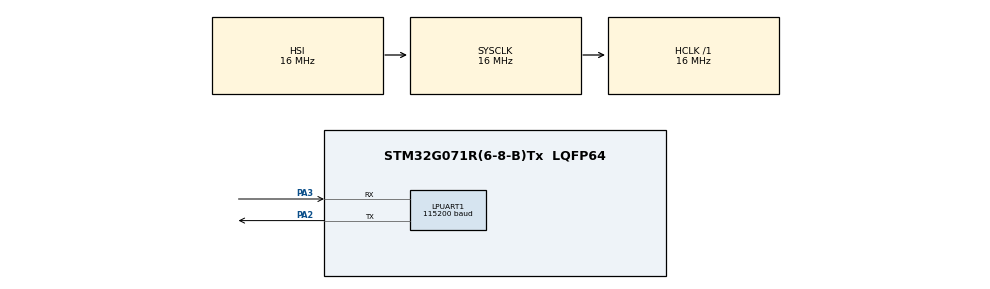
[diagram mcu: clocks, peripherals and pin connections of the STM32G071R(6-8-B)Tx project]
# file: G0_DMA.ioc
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Dma.LPUART1_RX.0.Direction=DMA_PERIPH_TO_MEMORY
Dma.LPUART1_RX.0.EventEnable=DISABLE
Dma.LPUART1_RX.0.Instance=DMA1_Channel1
Dma.LPUART1_RX.0.MemDataAlignment=DMA_MDATAALIGN_BYTE
Dma.LPUART1_RX.0.MemInc=DMA_MINC_ENABLE
Dma.LPUART1_RX.0.Mode=DMA_NORMAL
Dma.LPUART1_RX.0.PeriphDataAlignment=DMA_PDATAALIGN_BYTE
Dma.LPUART1_RX.0.PeriphInc=DMA_PINC_DISABLE
Dma.LPUART1_RX.0.Polarity=HAL_DMAMUX_REQ_GEN_RISING
Dma.LPUART1_RX.0.Priority=DMA_PRIORITY_LOW
Dma.LPUART1_RX.0.RequestNumber=1
Dma.LPUART1_RX.0.SyncEnable=DISABLE
Dma.LPUART1_RX.0.SyncPolarity=HAL_DMAMUX_SYNC_NO_EVENT
Dma.LPUART1_RX.0.SyncRequestNumber=1
Dma.LPUART1_TX.1.Direction=DMA_MEMORY_TO_PERIPH
Dma.LPUART1_TX.1.EventEnable=DISABLE
Dma.LPUART1_TX.1.Instance=DMA1_Channel2
Dma.LPUART1_TX.1.MemDataAlignment=DMA_MDATAALIGN_BYTE
Dma.LPUART1_TX.1.MemInc=DMA_MINC_ENABLE
Dma.LPUART1_TX.1.Mode=DMA_NORMAL
Dma.LPUART1_TX.1.PeriphDataAlignment=DMA_PDATAALIGN_BYTE
Dma.LPUART1_TX.1.PeriphInc=DMA_PINC_DISABLE
Dma.LPUART1_TX.1.Polarity=HAL_DMAMUX_REQ_GEN_RISING
Dma.LPUART1_TX.1.Priority=DMA_PRIORITY_LOW
Dma.LPUART1_TX.1.RequestNumber=1
Dma.LPUART1_TX.1.SyncEnable=DISABLE
Dma.LPUART1_TX.1.SyncPolarity=HAL_DMAMUX_SYNC_NO_EVENT
Dma.LPUART1_TX.1.SyncRequestNumber=1
Dma.Request0=LPUART1_RX
Dma.Request1=LPUART1_TX
LPUART1.BaudRate=115200
LPUART1.WordLength=UART_WORDLENGTH_8B
Mcu.Family=STM32G0
Mcu.Name=STM32G071R(6-8-B)Tx
Mcu.Package=LQFP64
NVIC.DMA1_Channel1_IRQn=true\:0\:0\:false\:false\:true\:false
NVIC.DMA1_Channel2_3_IRQn=true\:0\:0\:false\:false\:true\:false
PA2.Mode=Asynchronous
PA2.Signal=LPUART1_TX
PA3.Mode=Asynchronous
PA3.Signal=LPUART1_RX
ProjectManager.HeapSize=0x200
ProjectManager.StackSize=0x400
ProjectManager.TargetToolchain=MDK-ARM V5
RCC.AHBFreq_Value=16000000
RCC.CortexFreq_Value=16000000
RCC.EXTERNAL_CLOCK_VALUE=48000
RCC.HCLKFreq_Value=16000000
RCC.HSE_VALUE=8000000
RCC.HSI_VALUE=16000000
RCC.LSE_VALUE=32768
RCC.SYSCLKFreq_VALUE=16000000
RCC.VCOOutputFreq_Value=128000000
board=custom

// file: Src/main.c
/* USER CODE BEGIN Header */
/**
  ******************************************************************************
  * @file           : main.c
  * @brief          : Main program body
  ******************************************************************************
  ** This notice applies to any and all portions of this file
  * that are not between comment pairs USER CODE BEGIN and
  * USER CODE END. Other portions of this file, whether
  * inserted by the user or by software development tools
  * are owned by their respective copyright owners.
  *
  * COPYRIGHT(c) 2019 STMicroelectronics
  *
  * Redistribution and use in source and binary forms, with or without modification,
  * are permitted provided that the following conditions are met:
  *   1. Redistributions of source code must retain the above copyright notice,
  *      this list of conditions and the following disclaimer.
  *   2. Redistributions in binary form must reproduce the above copyright notice,
  *      this list of conditions and the following disclaimer in the documentation
  *      and/or other materials provided with the distribution.
  *   3. Neither the name of STMicroelectronics nor the names of its contributors
  *      may be used to endorse or promote products derived from this software
  *      without specific prior written permission.
  *
  * THIS SOFTWARE IS PROVIDED BY THE COPYRIGHT HOLDERS AND CONTRIBUTORS "AS IS"
  * AND ANY EXPRESS OR IMPLIED WARRANTIES, INCLUDING, BUT NOT LIMITED TO, THE
  * IMPLIED WARRANTIES OF MERCHANTABILITY AND FITNESS FOR A PARTICULAR PURPOSE ARE
  * DISCLAIMED. IN NO EVENT SHALL THE COPYRIGHT HOLDER OR CONTRIBUTORS BE LIABLE
  * FOR ANY DIRECT, INDIRECT, INCIDENTAL, SPECIAL, EXEMPLARY, OR CONSEQUENTIAL
  * DAMAGES (INCLUDING, BUT NOT LIMITED TO, PROCUREMENT OF SUBSTITUTE GOODS OR
  * SERVICES; LOSS OF USE, DATA, OR PROFITS; OR BUSINESS INTERRUPTION) HOWEVER
  * CAUSED AND ON ANY THEORY OF LIABILITY, WHETHER IN CONTRACT, STRICT LIABILITY,
  * OR TORT (INCLUDING NEGLIGENCE OR OTHERWISE) ARISING IN ANY WAY OUT OF THE USE
  * OF THIS SOFTWARE, EVEN IF ADVISED OF THE POSSIBILITY OF SUCH DAMAGE.
  *
  ******************************************************************************
  */
/* USER CODE END Header */

#include "main.h"

UART_HandleTypeDef hlpuart1;
DMA_HandleTypeDef hdma_lpuart1_rx;
DMA_HandleTypeDef hdma_lpuart1_tx;

/* USER CODE BEGIN PV */
uint8_t bufferTX [] = {117,27,3};	//data to be transmitted
uint8_t bufferRX [3];	//data to be received from the uart DMA
/* USER CODE END PV */

void SystemClock_Config(void);
static void MX_GPIO_Init(void);
static void MX_DMA_Init(void);
static void MX_LPUART1_UART_Init(void);

int main(void)
{

  /* MCU Configuration--------------------------------------------------------*/

  /* Reset of all peripherals, Initializes the Flash interface and the Systick. */
  HAL_Init();

  /* Configure the system clock */
  SystemClock_Config();

  /* Initialize all configured peripherals */
  MX_GPIO_Init();
  MX_DMA_Init();
  MX_LPUART1_UART_Init();
  /* USER CODE BEGIN 2 */
		HAL_UART_Receive_DMA(&hlpuart1, bufferTX, 3);		//place a jumper cable between the two pins!
	HAL_UART_Transmit_DMA(&hlpuart1, bufferTX, 3);

  /* USER CODE END 2 */

  /* Infinite loop */
  while (1)
  {

  }
}

void SystemClock_Config(void)
{
  RCC_OscInitTypeDef RCC_OscInitStruct = {0};
  RCC_ClkInitTypeDef RCC_ClkInitStruct = {0};
  RCC_PeriphCLKInitTypeDef PeriphClkInit = {0};

  /**Configure the main internal regulator output voltage
  */
  HAL_PWREx_ControlVoltageScaling(PWR_REGULATOR_VOLTAGE_SCALE1);
  /**Initializes the CPU, AHB and APB busses clocks
  */
  RCC_OscInitStruct.OscillatorType = RCC_OSCILLATORTYPE_HSI;
  RCC_OscInitStruct.HSIState = RCC_HSI_ON;
  RCC_OscInitStruct.HSIDiv = RCC_HSI_DIV1;
  RCC_OscInitStruct.HSICalibrationValue = RCC_HSICALIBRATION_DEFAULT;
  RCC_OscInitStruct.PLL.PLLState = RCC_PLL_NONE;
  if (HAL_RCC_OscConfig(&RCC_OscInitStruct) != HAL_OK)
  {
    Error_Handler();
  }
  /**Initializes the CPU, AHB and APB busses clocks
  */
  RCC_ClkInitStruct.ClockType = RCC_CLOCKTYPE_HCLK|RCC_CLOCKTYPE_SYSCLK
                              |RCC_CLOCKTYPE_PCLK1;
  RCC_ClkInitStruct.SYSCLKSource = RCC_SYSCLKSOURCE_HSI;
  RCC_ClkInitStruct.AHBCLKDivider = RCC_SYSCLK_DIV1;
  RCC_ClkInitStruct.APB1CLKDivider = RCC_HCLK_DIV1;

  if (HAL_RCC_ClockConfig(&RCC_ClkInitStruct, FLASH_LATENCY_0) != HAL_OK)
  {
    Error_Handler();
  }
  /**Initializes the peripherals clocks
  */
  PeriphClkInit.PeriphClockSelection = RCC_PERIPHCLK_LPUART1;
  PeriphClkInit.Lpuart1ClockSelection = RCC_LPUART1CLKSOURCE_PCLK1;
  if (HAL_RCCEx_PeriphCLKConfig(&PeriphClkInit) != HAL_OK)
  {
    Error_Handler();
  }
}

static void MX_LPUART1_UART_Init(void)
{

  hlpuart1.Instance = LPUART1;
  hlpuart1.Init.BaudRate = 115200;
  hlpuart1.Init.WordLength = UART_WORDLENGTH_8B;
  hlpuart1.Init.StopBits = UART_STOPBITS_1;
  hlpuart1.Init.Parity = UART_PARITY_NONE;
  hlpuart1.Init.Mode = UART_MODE_TX_RX;
  hlpuart1.Init.HwFlowCtl = UART_HWCONTROL_NONE;
  hlpuart1.Init.OneBitSampling = UART_ONE_BIT_SAMPLE_DISABLE;
  hlpuart1.Init.ClockPrescaler = UART_PRESCALER_DIV1;
  hlpuart1.AdvancedInit.AdvFeatureInit = UART_ADVFEATURE_NO_INIT;
  hlpuart1.FifoMode = UART_FIFOMODE_DISABLE;
  if (HAL_UART_Init(&hlpuart1) != HAL_OK)
  {
    Error_Handler();
  }
  if (HAL_UARTEx_SetTxFifoThreshold(&hlpuart1, UART_TXFIFO_THRESHOLD_1_8) != HAL_OK)
  {
    Error_Handler();
  }
  if (HAL_UARTEx_SetRxFifoThreshold(&hlpuart1, UART_RXFIFO_THRESHOLD_1_8) != HAL_OK)
  {
    Error_Handler();
  }
  if (HAL_UARTEx_DisableFifoMode(&hlpuart1) != HAL_OK)
  {
    Error_Handler();
  }

}

static void MX_DMA_Init(void)
{
  /* DMA controller clock enable */
  __HAL_RCC_DMA1_CLK_ENABLE();

  /* DMA interrupt init */
  /* DMA1_Channel1_IRQn interrupt configuration */
  HAL_NVIC_SetPriority(DMA1_Channel1_IRQn, 0, 0);
  HAL_NVIC_EnableIRQ(DMA1_Channel1_IRQn);
  /* DMA1_Channel2_3_IRQn interrupt configuration */
  HAL_NVIC_SetPriority(DMA1_Channel2_3_IRQn, 0, 0);
  HAL_NVIC_EnableIRQ(DMA1_Channel2_3_IRQn);

}

static void MX_GPIO_Init(void)
{

  /* GPIO Ports Clock Enable */
  __HAL_RCC_GPIOA_CLK_ENABLE();

}

/* USER CODE BEGIN 4 */

void HAL_UART_RX_Callback(UART_HandleTypeDef *hlpuart){
	__NOP(); //for debugging
}

void HAL_UART_TX_Callback(UART_HandleTypeDef *hlpuart){
	__NOP(); //for debugging
}

/* USER CODE END 4 */

void Error_Handler(void)
{
}

/************************ (C) COPYRIGHT STMicroelectronics *****END OF FILE****/
